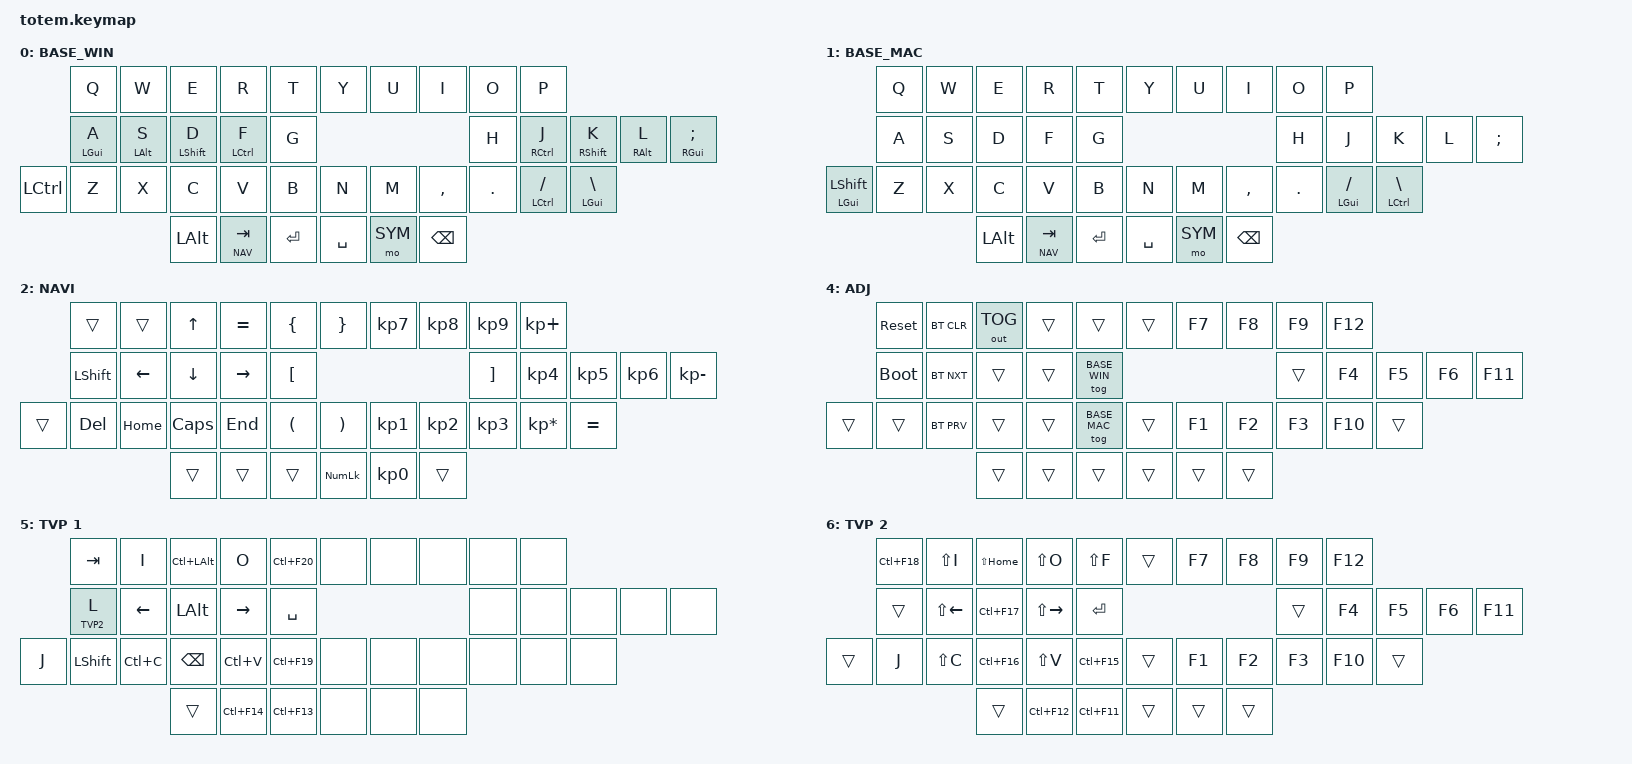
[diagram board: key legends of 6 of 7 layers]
//
//                                                        ▀▀▀▀▀     ▀▀▀▀▀          ▀▀█▀▀
//                                                        ▄▀▀▀▄  ▄  ▄▀▀▀▄  ▄  ▄▀▀▀▄  █  ▄▀▀▀▄
//                                                        █   █  █  █   █  █  █   █  █  █   █
//                                                         ▀▀▀   █   ▀▀▀   █   ▀▀▀   ▀   ▀▀▀
//                                                               █      ▄▄▄█▄▄▄    █   █  
//                                                               ▀      █  █  █     █▄█
//                                                             ▀▀▀▀▀    █  █  █      ▀
//                                                                      ▀  ▀  ▀
//
// ▄▄▄▄▄▄▄▄▄▄▄▄▄▄▄▄▄▄▄▄▄▄▄▄▄▄▄▄▄▄▄▄▄▄▄▄▄▄▄▄▄▄▄▄▄▄▄▄▄▄▄▄▄▄▄▄▄▄▄▄▄▄▄▄▄▄▄▄▄▄▄▄▄▄▄▄▄▄▄▄▄▄▄▄▄▄▄▄▄▄▄▄▄▄▄▄▄▄▄▄▄▄▄▄▄▄▄▄▄▄▄▄▄▄▄▄▄▄▄▄▄▄▄▄▄▄▄▄▄▄▄▄▄▄▄▄▄▄▄▄▄▄▄▄▄▄▄▄▄
       

#include <behaviors.dtsi>
#include <dt-bindings/zmk/keys.h>
#include <dt-bindings/zmk/bt.h>
#include <dt-bindings/zmk/outputs.h>

#define BASE_WIN 0
#define BASE_MAC 1
#define NAV  2
#define SYM  3
#define ADJ  4
#define TVP1 5
#define TVP2 6

&mt {
  quick-tap-ms = <150>;
  global-quick-tap;
  flavor = "tap-preferred";
  tapping-term-ms = <300>;
};

/ {
     combos {
            compatible = "zmk,combos";
            combo_esc {
                timeout-ms = <50>;
                key-positions = <0 1>;
                bindings = <&kp ESC>;
            };
            combo_taskm {
                timeout-ms = <50>;
                key-positions = <9 31>;
                bindings = <&ctrlaltdel>;
            };
    };

    macros {
        gif: gif {
            label = "giphy";
            compatible = "zmk,behavior-macro";
            #binding-cells = <0>;
            bindings
                = <&macro_press &kp LSHFT>
                , <&macro_tap &kp N2>
                , <&macro_release &kp LSHFT>
                , <&macro_tap &kp G &kp I &kp F>
                ;
        };
        ctrlaltdel: ctrlaltdel {
            label = "Ctrl+Alt+Del";
            compatible = "zmk,behavior-macro";
            #binding-cells = <0>;
            bindings =
                <&macro_press &kp LCTRL>
                , <&macro_press &kp LALT>
                , <&macro_press &kp DEL>
                , <&macro_release &kp DEL>
                , <&macro_release &kp LALT>
                , <&macro_release &kp LCTRL>
                ;
        };
    };

        keymap {
                compatible = "zmk,keymap";
// ▄▄▄▄▄▄▄▄▄▄▄▄▄▄▄▄▄▄▄▄▄▄▄▄▄▄▄▄▄▄▄▄▄▄▄▄▄▄▄▄▄▄▄▄▄▄▄▄▄▄▄▄▄▄▄▄▄▄▄▄▄▄▄▄▄▄▄▄▄▄▄▄▄▄▄▄▄▄▄▄▄▄▄▄▄▄▄▄▄▄▄▄▄▄▄▄▄▄▄▄▄▄▄▄▄▄▄▄▄▄▄▄▄▄▄▄▄▄▄▄▄▄▄▄▄▄▄▄▄▄▄▄▄▄▄▄▄▄▄▄▄▄▄▄▄▄▄▄▄

                base_layer {
// ┏━━━━━━━━━━━━━━━━━━━━━━━━━━━━━━━━━━━━━━━┓
label= "BASE_WIN"                              ;
// ┗━━━━━━━━━━━━━━━━━━━━━━━━━━━━━━━━━━━━━━━┛
//             ┏━━━━━━━━━━━┳━━━━━━━━━━━┳━━━━━━━━━━━┳━━━━━━━━━━━┳━━━━━━━━━━━┓   ┏━━━━━━━━━━━┳━━━━━━━━━━━┳━━━━━━━━━━━┳━━━━━━━━━━━┳━━━━━━━━━━━┓
//             ┃  0:Q      ┃  1:W      ┃  2:E      ┃  3:R      ┃  4:T      ┃   ┃  5:Y      ┃  6:U      ┃  7:I      ┃  8:O      ┃  9:P      ┃
//             ┣━━━━━━━━━━━╋━━━━━━━━━━━╋━━━━━━━━━━━╋━━━━━━━━━━━╋━━━━━━━━━━━┫   ┣━━━━━━━━━━━╋━━━━━━━━━━━╋━━━━━━━━━━━╋━━━━━━━━━━━╋━━━━━━━━━━━┫
//             ┃ 10:A      ┃ 11:S      ┃ 12:D      ┃ 13:F      ┃ 14:G      ┃   ┃ 15:H      ┃ 16:J      ┃ 17:K      ┃ 18:L      ┃ 19:;      ┃
// ┏━━━━━━━━━━━╋━━━━━━━━━━━╋━━━━━━━━━━━╋━━━━━━━━━━━╋━━━━━━━━━━━╋━━━━━━━━━━━┫   ┣━━━━━━━━━━━╋━━━━━━━━━━━╋━━━━━━━━━━━╋━━━━━━━━━━━╋━━━━━━━━━━━╋━━━━━━━━━━━┓
// ┃ 20:LSHFT  ┃ 21:Z      ┃ 22:X      ┃ 23:C      ┃ 24:V      ┃ 25:B      ┃   ┃ 26:N      ┃ 27:M      ┃ 28:,      ┃ 29:.      ┃ 30:Ctrl/  ┃ 31:GUI\   ┃
// ┗━━━━━━━━━━━┻━━━━━━━━━━━┻━━━━━━━━━━━╋━━━━━━━━━━━╋━━━━━━━━━━━╋━━━━━━━━━━━┫   ┣━━━━━━━━━━━╋━━━━━━━━━━━╋━━━━━━━━━━━╋━━━━━━━━━━━┻━━━━━━━━━━━┻━━━━━━━━━━━┛
//                                     ┃ 32:LALT   ┃ 33:LT_NAV_TAB ┃ 34:RET ┃  ┃ 35:SPC    ┃ 36:LT_SYM_ESC ┃ 37:BSPC┃
//                                     ┗━━━━━━━━━━━┻━━━━━━━━━━━┻━━━━━━━━━━━┛   ┗━━━━━━━━━━━┻━━━━━━━━━━━┻━━━━━━━━━━━┛
 bindings = <
// ╷           ╷           ╷           ╷           ╷           ╷           ╷   ╷           ╷           ╷           ╷           ╷           ╷           ╷

                &kp Q       &kp W       &kp E       &kp R       &kp T           &kp Y       &kp U       &kp I       &kp O       &kp P
                &mt LGUI A       &mt LALT S       &mt LSHFT D       &mt LCTRL F       &kp G           &kp H       &mt RCTRL J       &mt RSHFT K       &mt RALT L       &mt RGUI SEMI
&kp LCTRL       &kp Z       &kp X       &kp C       &kp V       &kp B           &kp N       &kp M       &kp COMMA   &kp DOT     &mt LCTRL FSLH    &mt LGUI BSLH
                                        &kp LALT    &lt NAV TAB &kp RET         &kp SPC     &mo SYM   &kp BSPC
                        >;
                };

// ▄▄▄▄▄▄▄▄▄▄▄▄▄▄▄▄▄▄▄▄▄▄▄▄▄▄▄▄▄▄▄▄▄▄▄▄▄▄▄▄▄▄▄▄▄▄▄▄▄▄▄▄▄▄▄▄▄▄▄▄▄▄▄▄▄▄▄▄▄▄▄▄▄▄▄▄▄▄▄▄▄▄▄▄▄▄▄▄▄▄▄▄▄▄▄▄▄▄▄▄▄▄▄▄▄▄▄▄▄▄▄▄▄▄▄▄▄▄▄▄▄▄▄▄▄▄▄▄▄▄▄▄▄▄▄▄▄▄▄▄▄▄▄▄▄▄▄▄▄

base_mac_layer {
        label = "BASE_MAC";
        bindings = <
                &kp Q           &kp W           &kp E           &kp R           &kp T           &kp Y           &kp U           &kp I           &kp O           &kp P
                &kp A           &kp S           &kp D           &kp F           &kp G           &kp H           &kp J           &kp K           &kp L           &kp SEMI
&mt LGUI LSHFT  &kp Z           &kp X           &kp C           &kp V           &kp B           &kp N           &kp M           &kp COMMA       &kp DOT         &mt LGUI FSLH &mt LCTRL BSLH
                                &kp LALT        &lt NAV TAB     &kp RET         &kp SPC         &mo SYM     &kp BSPC
        >;
    };

                nav_layer {
// ┏━━━━━━━━━━━━━━━━━━━━━━━━━━━━━━━━━━━━━━━┓
label= "NAVI"                              ;
// ┗━━━━━━━━━━━━━━━━━━━━━━━━━━━━━━━━━━━━━━━┛
//             ┏━━━━━━━━━━━┳━━━━━━━━━━━┳━━━━━━━━━━━┳━━━━━━━━━━━┳━━━━━━━━━━━┓   ┏━━━━━━━━━━━┳━━━━━━━━━━━┳━━━━━━━━━━━┳━━━━━━━━━━━┳━━━━━━━━━━━┓
//             ┃           ┃           ┃     UP    ┃           ┃     {     ┃   ┃     }     ┃     7     ┃     8     ┃     9     ┃     +     ┃
//             ┣━━━━━━━━━━━╋━━━━━━━━━━━╋━━━━━━━━━━━╋━━━━━━━━━━━╋━━━━━━━━━━━┫   ┣━━━━━━━━━━━╋━━━━━━━━━━━╋━━━━━━━━━━━╋━━━━━━━━━━━╋━━━━━━━━━━━┫
//             ┃   SHIFT   ┃   LEFT    ┃    DOWN   ┃   RIGHT   ┃     [     ┃   ┃     ]     ┃     4     ┃     5     ┃     6     ┃     -     ┃
// ┏━━━━━━━━━━━╋━━━━━━━━━━━╋━━━━━━━━━━━╋━━━━━━━━━━━╋━━━━━━━━━━━╋━━━━━━━━━━━┫   ┣━━━━━━━━━━━╋━━━━━━━━━━━╋━━━━━━━━━━━╋━━━━━━━━━━━╋━━━━━━━━━━━╋━━━━━━━━━━━┓
// ┃           ┃           ┃   P UP    ┃  C LOCK   ┃  P DOWN   ┃     (     ┃   ┃     )     ┃     1     ┃     2     ┃     3     ┃     *     ┃           ┃
// ┗━━━━━━━━━━━┻━━━━━━━━━━━┻━━━━━━━━━━━╋━━━━━━━━━━━╋━━━━━━━━━━━╋━━━━━━━━━━━┫   ┣━━━━━━━━━━━╋━━━━━━━━━━━╋━━━━━━━━━━━╋━━━━━━━━━━━┻━━━━━━━━━━━┻━━━━━━━━━━━┛
//                                     ┃           ┃    TAB    ┃    SPC    ┃   ┃    DEL    ┃     0     ┃           ┃
//                                     ┗━━━━━━━━━━━┻━━━━━━━━━━━┻━━━━━━━━━━━┛   ┗━━━━━━━━━━━┻━━━━━━━━━━━┻━━━━━━━━━━━┛
 bindings = <
// ╷           ╷           ╷           ╷           ╷           ╷           ╷   ╷           ╷           ╷           ╷           ╷           ╷           ╷

                &trans    &trans     &kp UP      &kp EQUAL   &kp LBRC        &kp RBRC    &kp KP_N7   &kp KP_N8   &kp KP_N9   &kp KP_PLUS
                &kp LSHFT   &kp LEFT    &kp DOWN    &kp RIGHT   &kp LBKT        &kp RBKT    &kp KP_N4   &kp KP_N5   &kp KP_N6   &kp KP_MINUS
    &trans      &kp DEL     &kp HOME   &kp CAPS    &kp END   &kp LPAR        &kp RPAR    &kp KP_N1   &kp KP_N2   &kp KP_N3   &kp KP_MULTIPLY &kp EQUAL      
                                        &trans      &trans      &trans          &kp KP_NUMLOCK     &kp KP_N0   &trans      
                        >;
                };

// ▄▄▄▄▄▄▄▄▄▄▄▄▄▄▄▄▄▄▄▄▄▄▄▄▄▄▄▄▄▄▄▄▄▄▄▄▄▄▄▄▄▄▄▄▄▄▄▄▄▄▄▄▄▄▄▄▄▄▄▄▄▄▄▄▄▄▄▄▄▄▄▄▄▄▄▄▄▄▄▄▄▄▄▄▄▄▄▄▄▄▄▄▄▄▄▄▄▄▄▄▄▄▄▄▄▄▄▄▄▄▄▄▄▄▄▄▄▄▄▄▄▄▄▄▄▄▄▄▄▄▄▄▄▄▄▄▄▄▄▄▄▄▄▄▄▄▄▄▄


                sim_layer {
// ┏━━━━━━━━━━━━━━━━━━━━━━━━━━━━━━━━━━━━━━━┓
label= "SYM"                               ;
// ┗━━━━━━━━━━━━━━━━━━━━━━━━━━━━━━━━━━━━━━━┛
//             ┏━━━━━━━━━━━┳━━━━━━━━━━━┳━━━━━━━━━━━┳━━━━━━━━━━━┳━━━━━━━━━━━┓   ┏━━━━━━━━━━━┳━━━━━━━━━━━┳━━━━━━━━━━━┳━━━━━━━━━━━┳━━━━━━━━━━━┓
//             ┃     !     ┃     @     ┃     #     ┃     $     ┃     %     ┃   ┃     ˆ     ┃     &     ┃     Ü     ┃     '     ┃     "     ┃
//             ┣━━━━━━━━━━━╋━━━━━━━━━━━╋━━━━━━━━━━━╋━━━━━━━━━━━╋━━━━━━━━━━━┫   ┣━━━━━━━━━━━╋━━━━━━━━━━━╋━━━━━━━━━━━╋━━━━━━━━━━━╋━━━━━━━━━━━┫
//             ┃     Ä     ┃           ┃    SZ     ┃           ┃           ┃   ┃   MUTE    ┃   YEN     ┃   EURO    ┃  POUND    ┃     Ö     ┃
// ┏━━━━━━━━━━━╋━━━━━━━━━━━╋━━━━━━━━━━━╋━━━━━━━━━━━╋━━━━━━━━━━━╋━━━━━━━━━━━┫   ┣━━━━━━━━━━━╋━━━━━━━━━━━╋━━━━━━━━━━━╋━━━━━━━━━━━╋━━━━━━━━━━━╋━━━━━━━━━━━┓
// ┃           ┃  EMAIL1   ┃  EMAIL2   ┃           ┃           ┃           ┃   ┃   VOL-    ┃   VOL+    ┃   LAST    ┃   NEXT    ┃     \     ┃           ┃
// ┗━━━━━━━━━━━┻━━━━━━━━━━━┻━━━━━━━━━━━╋━━━━━━━━━━━╋━━━━━━━━━━━╋━━━━━━━━━━━┫   ┣━━━━━━━━━━━╋━━━━━━━━━━━╋━━━━━━━━━━━╋━━━━━━━━━━━┻━━━━━━━━━━━┻━━━━━━━━━━━┛
//                                     ┃           ┃    GIF    ┃    ADJ    ┃   ┃           ┃           ┃           ┃
//                                     ┗━━━━━━━━━━━┻━━━━━━━━━━━┻━━━━━━━━━━━┛   ┗━━━━━━━━━━━┻━━━━━━━━━━━┻━━━━━━━━━━━┛
 bindings = <
// ╷           ╷           ╷           ╷           ╷           ╷           ╷   ╷           ╷           ╷           ╷           ╷           ╷           ╷

                &kp EXCL    &kp AT      &kp HASH    &kp DLLR    &kp PRCNT       &kp CARET   &kp AMPS    &kp RA(U)   &kp SQT     &kp DQT       
                &kp RA(A)   &trans      &kp RA(S)   &trans      &trans          &kp C_MUTE  &trans &trans &trans   &trans 
    &trans      &kp RA(F18) &kp RA(F19) &trans      &trans      &trans          &kp C_VOL_DN &kp C_VOL_UP &kp LC(PRINTSCREEN) &trans  &kp MINUS   &trans         
                                        &trans      &gif        &mo ADJ         &trans      &kp C_PP    &trans       
                                        &trans      &gif        &mo ADJ         &trans      &kp K_PP    &trans       
                        >;
                };

// ▄▄▄▄▄▄▄▄▄▄▄▄▄▄▄▄▄▄▄▄▄▄▄▄▄▄▄▄▄▄▄▄▄▄▄▄▄▄▄▄▄▄▄▄▄▄▄▄▄▄▄▄▄▄▄▄▄▄▄▄▄▄▄▄▄▄▄▄▄▄▄▄▄▄▄▄▄▄▄▄▄▄▄▄▄▄▄▄▄▄▄▄▄▄▄▄▄▄▄▄▄▄▄▄▄▄▄▄▄▄▄▄▄▄▄▄▄▄▄▄▄▄▄▄▄▄▄▄▄▄▄▄▄▄▄▄▄▄▄▄▄▄▄▄▄▄▄▄▄


                adjust_layer {
// ┏━━━━━━━━━━━━━━━━━━━━━━━━━━━━━━━━━━━━━━━┓
label= "ADJ"                               ;
// ┗━━━━━━━━━━━━━━━━━━━━━━━━━━━━━━━━━━━━━━━┛
//             ┏━━━━━━━━━━━┳━━━━━━━━━━━┳━━━━━━━━━━━┳━━━━━━━━━━━┳━━━━━━━━━━━┓   ┏━━━━━━━━━━━┳━━━━━━━━━━━┳━━━━━━━━━━━┳━━━━━━━━━━━┳━━━━━━━━━━━┓
//             ┃   RESET   ┃ BT CLEAR  ┃  OUT TOG  ┃           ┃           ┃   ┃           ┃    F7     ┃    F8     ┃    F9     ┃    F12    ┃
//             ┣━━━━━━━━━━━╋━━━━━━━━━━━╋━━━━━━━━━━━╋━━━━━━━━━━━╋━━━━━━━━━━━┫   ┣━━━━━━━━━━━╋━━━━━━━━━━━╋━━━━━━━━━━━╋━━━━━━━━━━━╋━━━━━━━━━━━┫
//             ┃ BOOTLOAD  ┃ BT NEXT   ┃           ┃           ┃           ┃   ┃           ┃    F4     ┃    F5     ┃    F6     ┃    F11    ┃
// ┏━━━━━━━━━━━╋━━━━━━━━━━━╋━━━━━━━━━━━╋━━━━━━━━━━━╋━━━━━━━━━━━╋━━━━━━━━━━━┫   ┣━━━━━━━━━━━╋━━━━━━━━━━━╋━━━━━━━━━━━╋━━━━━━━━━━━╋━━━━━━━━━━━╋━━━━━━━━━━━┓
// ┃           ┃           ┃ BT PREV   ┃           ┃           ┃           ┃   ┃           ┃    F1     ┃    F2     ┃    F3     ┃    F10    ┃           ┃
// ┗━━━━━━━━━━━┻━━━━━━━━━━━┻━━━━━━━━━━━╋━━━━━━━━━━━╋━━━━━━━━━━━╋━━━━━━━━━━━┫   ┣━━━━━━━━━━━╋━━━━━━━━━━━╋━━━━━━━━━━━╋━━━━━━━━━━━┻━━━━━━━━━━━┻━━━━━━━━━━━┛
//                                     ┃           ┃           ┃           ┃   ┃           ┃           ┃           ┃
//                                     ┗━━━━━━━━━━━┻━━━━━━━━━━━┻━━━━━━━━━━━┛   ┗━━━━━━━━━━━┻━━━━━━━━━━━┻━━━━━━━━━━━┛
 bindings = <
// ╷           ╷           ╷           ╷           ╷           ╷           ╷   ╷           ╷           ╷           ╷           ╷           ╷           ╷

                &sys_reset  &bt BT_CLR &out OUT_TOG &trans      &trans          &trans      &kp F7      &kp F8      &kp F9      &kp F12
                &bootloader &bt BT_NXT  &trans      &trans      &tog BASE_WIN   &trans      &kp F4      &kp F5      &kp F6      &kp F11  
    &trans      &trans      &bt BT_PRV  &trans      &trans      &tog BASE_MAC   &trans      &kp F1      &kp F2      &kp F3      &kp F10     &trans         
                                        &trans      &trans      &trans          &trans      &trans      &trans      
                        >;
                };

// ▄▄▄▄▄▄▄▄▄▄▄▄▄▄▄▄▄▄▄▄▄▄▄▄▄▄▄▄▄▄▄▄▄▄▄▄▄▄▄▄▄▄▄▄▄▄▄▄▄▄▄▄▄▄▄▄▄▄▄▄▄▄▄▄▄▄▄▄▄▄▄▄▄▄▄▄▄▄▄▄▄▄▄▄▄▄▄▄▄▄▄▄▄▄▄▄▄▄▄▄▄▄▄▄▄▄▄▄▄▄▄▄▄▄▄▄▄▄▄▄▄▄▄▄▄▄▄▄▄▄▄▄▄▄▄▄▄▄▄▄▄▄▄▄▄▄▄▄▄


                tvp1_layer {
// ┏━━━━━━━━━━━━━━━━━━━━━━━━━━━━━━━━━━━━━━━┓
label= "TVP 1"                             ;
// ┗━━━━━━━━━━━━━━━━━━━━━━━━━━━━━━━━━━━━━━━┛
//             ┏━━━━━━━━━━━┳━━━━━━━━━━━┳━━━━━━━━━━━┳━━━━━━━━━━─┳━━━━━━━━━━━┓   ┏━━━━━━━━━━━┳━━━━━━━━━━━┳━━━━━━━━━━━┳━━━━━━━━━━━┳━━━━━━━━━━━┓
//             ┃ NEXT FILE ┃ MARK IN   ┃ ROTATE    ┃ MARK OUT  ┃ SHOW SNAP ┃   ┃           ┃           ┃           ┃           ┃           ┃
//             ┣━━━━━━━━━━━╋━━━━━━━━━━━╋━━━━━━━━━━━╋━━━━━━━━━━━╋━━━━━━━━━━━┫   ┣━━━━━━━━━━━╋━━━━━━━━━━━╋━━━━━━━━━━━╋━━━━━━━━━━━╋━━━━━━━━━━━┫
//             ┃ TVP II    ┃ LEFT      ┃ PAN       ┃ RIGHT     ┃ PLAY/FLIP ┃   ┃           ┃           ┃           ┃           ┃           ┃
// ┏━━━━━━━━━━━╋━━━━━━━━━━━╋━━━━━━━━━━━╋━━━━━━━━━━━╋━━━━━━━━━━━╋━━━━━━━━━━━┫   ┣━━━━━━━━━━━╋━━━━━━━━━━━╋━━━━━━━━━━━╋━━━━━━━━━━━╋━━━━━━━━━━━╋━━━━━━━━━━━┓
// ┃ FULLSCR   ┃ SHIFT     ┃ COPY      ┃ DELETE    ┃ PASTE     ┃ IMG MARK  ┃   ┃           ┃           ┃           ┃           ┃           ┃           ┃
// ┗━━━━━━━━━━━┻━━━━━━━━━━━┻━━━━━━━━━━━╋━━━━━━━━━━━╋━━━━━━━━━━━╋━━━━━━━━━━━┫   ┣━━━━━━━━━━━╋━━━━━━━━━━━╋━━━━━━━━━━━╋━━━━━━━━━━━┻━━━━━━━━━━━┻━━━━━━━━━━━┛
//                                     ┃           ┃ UNDO/SAVE ┃  SEL/MOV  ┃   ┃           ┃           ┃           ┃
//                                     ┗━━━━━━━━━━━┻━━━━━━━━━━━┻━━━━━━━━━━━┛   ┗━━━━━━━━━━━┻━━━━━━━━━━━┻━━━━━━━━━━━┛
 bindings = <
// ╷           ╷           ╷           ╷           ╷           ╷           ╷   ╷           ╷           ╷           ╷           ╷           ╷           ╷

                &kp TAB     &kp I       &kp LC(LALT) &kp O      &kp LC(F20)     &none       &none       &none       &none       &none
                &lt TVP2 L  &kp LEFT    &kp LALT    &kp RIGHT   &kp SPACE       &none       &none       &none       &none       &none
    &kp J       &kp LSHFT   &kp LC(C)   &kp BSPC    &kp LC(V)   &kp LC(F19)     &none       &none       &none       &none       &none       &none        
                                        &trans      &kp LC(F14) &kp LC(F13)     &none       &none       &none    
                        >;
                };

// ▄▄▄▄▄▄▄▄▄▄▄▄▄▄▄▄▄▄▄▄▄▄▄▄▄▄▄▄▄▄▄▄▄▄▄▄▄▄▄▄▄▄▄▄▄▄▄▄▄▄▄▄▄▄▄▄▄▄▄▄▄▄▄▄▄▄▄▄▄▄▄▄▄▄▄▄▄▄▄▄▄▄▄▄▄▄▄▄▄▄▄▄▄▄▄▄▄▄▄▄▄▄▄▄▄▄▄▄▄▄▄▄▄▄▄▄▄▄▄▄▄▄▄▄▄▄▄▄▄▄▄▄▄▄▄▄▄▄▄▄▄▄▄▄▄▄▄▄▄


                tvp2_layer {
// ┏━━━━━━━━━━━━━━━━━━━━━━━━━━━━━━━━━━━━━━━┓
label= "TVP 2"                             ;
// ┗━━━━━━━━━━━━━━━━━━━━━━━━━━━━━━━━━━━━━━━┛
//             ┏━━━━━━━━━━━┳━━━━━━━━━━━┳━━━━━━━━━━━┳━━━━━━━━━━━┳━━━━━━━━━━━┓   ┏━━━━━━━━━━━┳━━━━━━━━━━━┳━━━━━━━━━━━┳━━━━━━━━━━━┳━━━━━━━━━━━┓
//             ┃ SOLO      ┃ TOGGLE IN ┃ RESET ROT ┃ TOGGLE OUT┃ TAKE SNAP ┃   ┃           ┃           ┃           ┃           ┃           ┃
//             ┣━━━━━━━━━━━╋━━━━━━━━━━━╋━━━━━━━━━━━╋━━━━━━━━━━━╋━━━━━━━━━━━┫   ┣━━━━━━━━━━━╋━━━━━━━━━━━╋━━━━━━━━━━━╋━━━━━━━━━━━╋━━━━━━━━━━━┫
//             ┃ ---       ┃ LAST KEY  ┃ NEW KEY   ┃ NEXT KEY  ┃ ENTER     ┃   ┃           ┃           ┃           ┃           ┃           ┃
// ┏━━━━━━━━━━━╋━━━━━━━━━━━╋━━━━━━━━━━━╋━━━━━━━━━━━╋━━━━━━━━━━━╋━━━━━━━━━━━┫   ┣━━━━━━━━━━━╋━━━━━━━━━━━╋━━━━━━━━━━━╋━━━━━━━━━━━╋━━━━━━━━━━━╋━━━━━━━━━━━┓
// ┃           ┃ FULLSCR   ┃ CPY2BRUSH ┃ DEL HEAD  ┃ PSTinPLACE┃ BOOK MARK ┃   ┃           ┃           ┃           ┃           ┃           ┃           ┃
// ┗━━━━━━━━━━━┻━━━━━━━━━━━┻━━━━━━━━━━━╋━━━━━━━━━━━╋━━━━━━━━━━━╋━━━━━━━━━━━┫   ┣━━━━━━━━━━━╋━━━━━━━━━━━╋━━━━━━━━━━━╋━━━━━━━━━━━┻━━━━━━━━━━━┻━━━━━━━━━━━┛
//                                     ┃           ┃ REDO/SAV1 ┃TRANS/WARP ┃   ┃           ┃           ┃           ┃
//                                     ┗━━━━━━━━━━━┻━━━━━━━━━━━┻━━━━━━━━━━━┛   ┗━━━━━━━━━━━┻━━━━━━━━━━━┻━━━━━━━━━━━┛
 bindings = <
// ╷           ╷           ╷           ╷           ╷           ╷           ╷   ╷           ╷           ╷           ╷           ╷           ╷           ╷

                &kp LC(F18) &kp LS(I)  &kp LS(HOME) &kp LS(O)   &kp LS(F)       &trans      &kp F7      &kp F8      &kp F9      &kp F12
                &trans      &kp LS(LEFT) &kp LC(F17) &kp LS(RIGHT) &kp RET      &trans      &kp F4      &kp F5      &kp F6      &kp F11  
    &trans      &kp J       &kp LS(C)   &kp LC(F16) &kp LS(V)   &kp LC(F15)     &trans      &kp F1      &kp F2      &kp F3      &kp F10     &trans         
                                        &trans      &kp LC(F12) &kp LC(F11)     &trans      &trans      &trans      
                        >;
                };
        };
};
